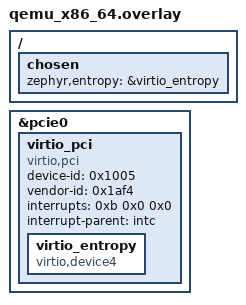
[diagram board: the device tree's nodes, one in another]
/*
 * Copyright (c) 2025 TOKITA Hiroshi
 *
 * SPDX-License-Identifier: Apache-2.0
 */

/ {
	chosen {
		zephyr,entropy = &virtio_entropy;
	};
};

&pcie0 {
	virtio_pci: virtio_pci {
		compatible = "virtio,pci";

		device-id = <0x1005>;
		vendor-id = <0x1af4>;

		interrupts = <0xb 0x0 0x0>;
		interrupt-parent = <&intc>;

		virtio_entropy: virtio_entropy {
			compatible = "virtio,device4";
		};
	};
};
